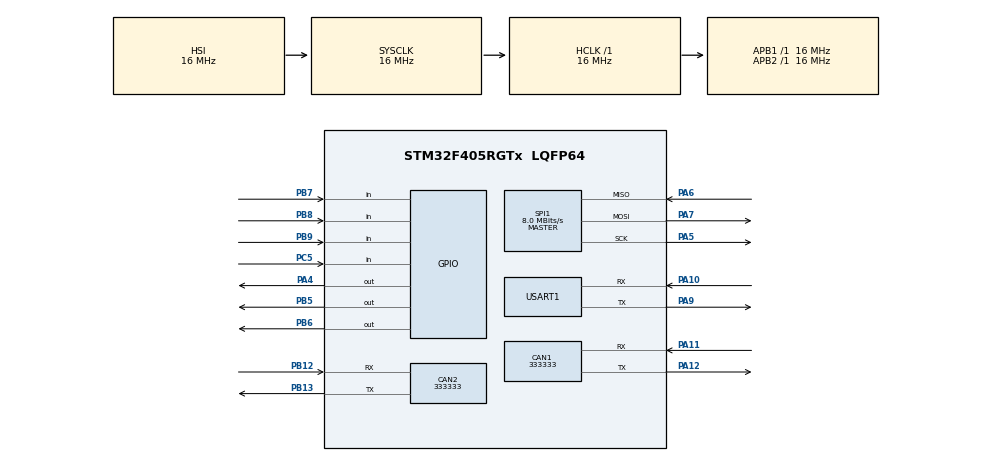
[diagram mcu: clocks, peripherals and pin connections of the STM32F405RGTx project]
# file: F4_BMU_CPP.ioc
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CAN1.CalculateBaudRate=333333
CAN1.CalculateTimeBit=3000
CAN1.CalculateTimeQuantum=1000.0
CAN2.CalculateBaudRate=333333
CAN2.CalculateTimeBit=3000
CAN2.CalculateTimeQuantum=1000.0
Mcu.Family=STM32F4
Mcu.Name=STM32F405RGTx
Mcu.Package=LQFP64
NVIC.PriorityGroup=NVIC_PRIORITYGROUP_4
NVIC.USART1_IRQn=true\:0\:0\:false\:false\:true\:true\:true\:true
PA10.Mode=Asynchronous
PA10.Signal=USART1_RX
PA11.Mode=CAN_Activate
PA11.Signal=CAN1_RX
PA12.Mode=CAN_Activate
PA12.Signal=CAN1_TX
PA13.Mode=JTAG_4_pins
PA13.Signal=SYS_JTMS-SWDIO
PA14.Mode=JTAG_4_pins
PA14.Signal=SYS_JTCK-SWCLK
PA15.Mode=JTAG_4_pins
PA15.Signal=SYS_JTDI
PA4.Signal=GPIO_Output
PA5.Mode=Full_Duplex_Master
PA5.Signal=SPI1_SCK
PA6.Mode=Full_Duplex_Master
PA6.Signal=SPI1_MISO
PA7.Mode=Full_Duplex_Master
PA7.Signal=SPI1_MOSI
PA9.Mode=Asynchronous
PA9.Signal=USART1_TX
PB12.Mode=CAN_Activate
PB12.Signal=CAN2_RX
PB13.Mode=CAN_Activate
PB13.Signal=CAN2_TX
PB3.Mode=JTAG_4_pins
PB3.Signal=SYS_JTDO-SWO
PB5.Signal=GPIO_Output
PB6.Signal=GPIO_Output
PB7.Signal=GPIO_Input
PB8.Signal=GPIO_Input
PB9.Signal=GPIO_Input
PC5.Signal=GPIO_Input
ProjectManager.HeapSize=0x200
ProjectManager.StackSize=0x400
ProjectManager.TargetToolchain=STM32CubeIDE
RCC.AHBFreq_Value=16000000
RCC.APB1Freq_Value=16000000
RCC.APB2Freq_Value=16000000
RCC.CortexFreq_Value=16000000
RCC.HSE_VALUE=25000000
RCC.HSI_VALUE=16000000
RCC.LSE_VALUE=32768
RCC.SYSCLKFreq_VALUE=16000000
RCC.VCOOutputFreq_Value=192000000
SPI1.CalculateBaudRate=8.0 MBits/s
SPI1.Direction=SPI_DIRECTION_2LINES
SPI1.Mode=SPI_MODE_MASTER
SPI1.VirtualType=VM_MASTER
USART1.VirtualMode=VM_ASYNC
VP_TIM1_VS_ClockSourceINT.Mode=Internal
VP_TIM1_VS_ClockSourceITR.Mode=TriggerSource_ITR0
VP_TIM1_VS_ControllerModeTrigger.Mode=Trigger Mode
board=custom

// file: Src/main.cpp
/* USER CODE BEGIN Header */
/**
  ******************************************************************************
  * @file           : main.c
  * @brief          : Main program body
  ******************************************************************************
  * @attention
  *
  * Copyright (c) 2024 STMicroelectronics.
  * All rights reserved.
  *
  * This software is licensed under terms that can be found in the LICENSE file
  * in the root directory of this software component.
  * If no LICENSE file comes with this software, it is provided AS-IS.
  *
  ******************************************************************************
  */
/* USER CODE END Header */
#include "main.h"
#include "can.h"
#include "spi.h"
#include "tim.h"
#include "usart.h"
#include "gpio.h"

/* USER CODE BEGIN Includes */
#include "bmu.h"

/* USER CODE END Includes */

void SystemClock_Config(void);

int main(void)
{

  /* MCU Configuration--------------------------------------------------------*/

  /* Reset of all peripherals, Initializes the Flash interface and the Systick. */
  HAL_Init();

  /* Configure the system clock */
  SystemClock_Config();

  /* Initialize all configured peripherals */
  MX_GPIO_Init();
  MX_SPI1_Init();
  MX_USART1_UART_Init();
  MX_CAN1_Init();
  MX_CAN2_Init();
  MX_TIM1_Init();

  /* Infinite loop */
  while (1)
  {

    /* USER CODE BEGIN 3 */
    uint8_t data[4] = {0x02, 0xB7, 0x78, 0xBC};
	  BMU* HR24E = new BMU();

	  HR24E->Wake79600();
	  HR24E->WriteFrame(0x01, 0x0100, data, 4, FRMWRT_SGL_W);

	  HR24E->ShutDown79600();
  }
  /* USER CODE END 3 */
}

void SystemClock_Config(void)
{
  RCC_OscInitTypeDef RCC_OscInitStruct = {0};
  RCC_ClkInitTypeDef RCC_ClkInitStruct = {0};

  /** Configure the main internal regulator output voltage
  */
  __HAL_RCC_PWR_CLK_ENABLE();
  __HAL_PWR_VOLTAGESCALING_CONFIG(PWR_REGULATOR_VOLTAGE_SCALE1);

  /** Initializes the RCC Oscillators according to the specified parameters
  * in the RCC_OscInitTypeDef structure.
  */
  RCC_OscInitStruct.OscillatorType = RCC_OSCILLATORTYPE_HSI;
  RCC_OscInitStruct.HSIState = RCC_HSI_ON;
  RCC_OscInitStruct.HSICalibrationValue = RCC_HSICALIBRATION_DEFAULT;
  RCC_OscInitStruct.PLL.PLLState = RCC_PLL_NONE;
  if (HAL_RCC_OscConfig(&RCC_OscInitStruct) != HAL_OK)
  {
    Error_Handler();
  }

  /** Initializes the CPU, AHB and APB buses clocks
  */
  RCC_ClkInitStruct.ClockType = RCC_CLOCKTYPE_HCLK|RCC_CLOCKTYPE_SYSCLK
                              |RCC_CLOCKTYPE_PCLK1|RCC_CLOCKTYPE_PCLK2;
  RCC_ClkInitStruct.SYSCLKSource = RCC_SYSCLKSOURCE_HSI;
  RCC_ClkInitStruct.AHBCLKDivider = RCC_SYSCLK_DIV1;
  RCC_ClkInitStruct.APB1CLKDivider = RCC_HCLK_DIV1;
  RCC_ClkInitStruct.APB2CLKDivider = RCC_HCLK_DIV1;

  if (HAL_RCC_ClockConfig(&RCC_ClkInitStruct, FLASH_LATENCY_0) != HAL_OK)
  {
    Error_Handler();
  }
}

void Error_Handler(void)
{
  __disable_irq();
  while (1)
  {
  }
}
